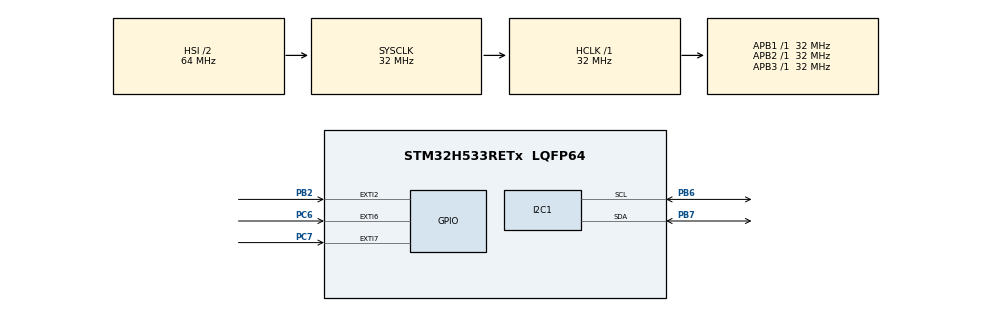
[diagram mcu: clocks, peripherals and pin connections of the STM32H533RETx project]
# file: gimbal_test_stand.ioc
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BOOTPATH.BootPathName=LEGACY
BOOTPATH.UserSelectedBootPath=LEGACY
CORTEX_M33_NS.Number-Cortex_Memory_Protection_Unit_Region0_OTP_RO_AREAS_Settings=MPU_REGION_NUMBER0
CORTEX_M33_NS.default_mode_Activation=1
CORTEX_M33_NS.userName=CORTEX_M33
I2C1.Timing=0x00707CBB
Mcu.Family=STM32H5
Mcu.Name=STM32H533RETx
Mcu.Package=LQFP64
NUCLEO-H533RE.BUTTON=1
NUCLEO-H533RE.LD4=true
NUCLEO-H533RE.VCP=true
NVIC.EXTI13_IRQn=true\:0\:0\:false\:false\:true\:false\:true\:true
NVIC.PriorityGroup=NVIC_PRIORITYGROUP_4
PA13(JTMS/SWDIO).GPIO_Label=SWDIO
PA13(JTMS/SWDIO).Signal=DEBUG_JTMS-SWDIO
PA14(JTCK/SWCLK).GPIO_Label=SWCLK
PA14(JTCK/SWCLK).Signal=DEBUG_JTCK-SWCLK
PA15(JTDI).GPIO_Label=JTDI
PA15(JTDI).Signal=DEBUG_JTDI
PA2.Signal=USART2_TX
PA3.Signal=USART2_RX
PA8.Signal=I2C3_SCL
PB2.Signal=GPXTI2
PB3(JTDO/TRACESWO).GPIO_Label=SWO
PB3(JTDO/TRACESWO).Signal=DEBUG_JTDO-SWO
PB6.Mode=I2C
PB6.Signal=I2C1_SCL
PB7.Mode=I2C
PB7.Signal=I2C1_SDA
PC6.Signal=GPXTI6
PC7.Signal=GPXTI7
PC9.Signal=I2C3_SDA
ProjectManager.HeapSize=0x200
ProjectManager.StackSize=0x400
ProjectManager.TargetToolchain=CMake
RCC.ADCFreq_Value=32000000
RCC.AHBFreq_Value=32000000
RCC.APB1Freq_Value=32000000
RCC.APB1TimFreq_Value=32000000
RCC.APB2Freq_Value=32000000
RCC.APB2TimFreq_Value=32000000
RCC.APB3Freq_Value=32000000
RCC.CSI_VALUE=4000000
RCC.CortexFreq_Value=32000000
RCC.EPOD_VALUE=4000000
RCC.HCLKFreq_Value=32000000
RCC.HSE_VALUE=25000000
RCC.HSI48_VALUE=48000000
RCC.HSI_VALUE=64000000
RCC.LSE_VALUE=32768
RCC.LSIRC_VALUE=32000
RCC.SYSCLKFreq_VALUE=32000000
RCC.USBFreq_Value=48000000
RCC.VCOOutputFreq_Value=516000000
VP_BOOTPATH_VS_BOOTPATH.Mode=BP_Activate
VP_CORTEX_M33_NS_VS_Hclk.Mode=Hclk_Mode
VP_ICACHE_VS_ICACHE.Mode=DirectMappedCache
VP_MEMORYMAP_VS_MEMORYMAP.Mode=CurAppReg
VP_NUCLEO-H533RE_VS_BSP_COMMON.Mode=COMMON
VP_PWR_VS_LPOM.Mode=PowerOptimisation
VP_PWR_VS_SECSignals.Mode=Security/Privilege
board=NUCLEO-H533RE

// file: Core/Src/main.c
/* USER CODE BEGIN Header */
/**
  ******************************************************************************
  * @file           : main.c
  * @brief          : Main program body
  ******************************************************************************
  * @attention
  *
  * Copyright (c) 2026 STMicroelectronics.
  * All rights reserved.
  *
  * This software is licensed under terms that can be found in the LICENSE file
  * in the root directory of this software component.
  * If no LICENSE file comes with this software, it is provided AS-IS.
  *
  ******************************************************************************
  */
/* USER CODE END Header */
#include "main.h"

/* USER CODE BEGIN Includes */
#include "as5600.h"

/* USER CODE END Includes */

COM_InitTypeDef BspCOMInit;

I2C_HandleTypeDef hi2c1;

/* USER CODE BEGIN PV */
static as5600_t g_as5600;
/* USER CODE END PV */

void SystemClock_Config(void);
static void MPU_Config(void);
static void MX_GPIO_Init(void);
static void MX_ICACHE_Init(void);
static void MX_I2C1_Init(void);

int main(void)
{

  /* MCU Configuration--------------------------------------------------------*/

  /* MPU Configuration--------------------------------------------------------*/
  MPU_Config();

  /* Reset of all peripherals, Initializes the Flash interface and the Systick. */
  HAL_Init();

  /* Configure the system clock */
  SystemClock_Config();

  /* Initialize all configured peripherals */
  MX_GPIO_Init();
  MX_ICACHE_Init();
  MX_I2C1_Init();
  /* USER CODE BEGIN 2 */

if (as5600_init(&g_as5600, &hi2c1, 10u) != AS5600_OK)
{
    Error_Handler();
}

  /* USER CODE END 2 */

  /* Initialize leds */
  BSP_LED_Init(LED_GREEN);

  /* Initialize USER push-button, will be used to trigger an interrupt each time it's pressed.*/
  BSP_PB_Init(BUTTON_USER, BUTTON_MODE_EXTI);

  /* Initialize COM1 port (115200, 8 bits (7-bit data + 1 stop bit), no parity */
  BspCOMInit.BaudRate   = 115200;
  BspCOMInit.WordLength = COM_WORDLENGTH_8B;
  BspCOMInit.StopBits   = COM_STOPBITS_1;
  BspCOMInit.Parity     = COM_PARITY_NONE;
  BspCOMInit.HwFlowCtl  = COM_HWCONTROL_NONE;
  if (BSP_COM_Init(COM1, &BspCOMInit) != BSP_ERROR_NONE)
  {
    Error_Handler();
  }

  /* Infinite loop */
  while (1)
  {

  }
}

void SystemClock_Config(void)
{
  RCC_OscInitTypeDef RCC_OscInitStruct = {0};
  RCC_ClkInitTypeDef RCC_ClkInitStruct = {0};

  /** Configure the main internal regulator output voltage
  */
  __HAL_PWR_VOLTAGESCALING_CONFIG(PWR_REGULATOR_VOLTAGE_SCALE3);

  while(!__HAL_PWR_GET_FLAG(PWR_FLAG_VOSRDY)) {}

  /** Initializes the RCC Oscillators according to the specified parameters
  * in the RCC_OscInitTypeDef structure.
  */
  RCC_OscInitStruct.OscillatorType = RCC_OSCILLATORTYPE_HSI;
  RCC_OscInitStruct.HSIState = RCC_HSI_ON;
  RCC_OscInitStruct.HSIDiv = RCC_HSI_DIV2;
  RCC_OscInitStruct.HSICalibrationValue = RCC_HSICALIBRATION_DEFAULT;
  RCC_OscInitStruct.PLL.PLLState = RCC_PLL_NONE;
  if (HAL_RCC_OscConfig(&RCC_OscInitStruct) != HAL_OK)
  {
    Error_Handler();
  }

  /** Initializes the CPU, AHB and APB buses clocks
  */
  RCC_ClkInitStruct.ClockType = RCC_CLOCKTYPE_HCLK|RCC_CLOCKTYPE_SYSCLK
                              |RCC_CLOCKTYPE_PCLK1|RCC_CLOCKTYPE_PCLK2
                              |RCC_CLOCKTYPE_PCLK3;
  RCC_ClkInitStruct.SYSCLKSource = RCC_SYSCLKSOURCE_HSI;
  RCC_ClkInitStruct.AHBCLKDivider = RCC_SYSCLK_DIV1;
  RCC_ClkInitStruct.APB1CLKDivider = RCC_HCLK_DIV1;
  RCC_ClkInitStruct.APB2CLKDivider = RCC_HCLK_DIV1;
  RCC_ClkInitStruct.APB3CLKDivider = RCC_HCLK_DIV1;

  if (HAL_RCC_ClockConfig(&RCC_ClkInitStruct, FLASH_LATENCY_1) != HAL_OK)
  {
    Error_Handler();
  }

  /** Configure the programming delay
  */
  __HAL_FLASH_SET_PROGRAM_DELAY(FLASH_PROGRAMMING_DELAY_0);
}

static void MX_I2C1_Init(void)
{

  hi2c1.Instance = I2C1;
  hi2c1.Init.Timing = 0x00707CBB;
  hi2c1.Init.OwnAddress1 = 0;
  hi2c1.Init.AddressingMode = I2C_ADDRESSINGMODE_7BIT;
  hi2c1.Init.DualAddressMode = I2C_DUALADDRESS_DISABLE;
  hi2c1.Init.OwnAddress2 = 0;
  hi2c1.Init.OwnAddress2Masks = I2C_OA2_NOMASK;
  hi2c1.Init.GeneralCallMode = I2C_GENERALCALL_DISABLE;
  hi2c1.Init.NoStretchMode = I2C_NOSTRETCH_DISABLE;
  if (HAL_I2C_Init(&hi2c1) != HAL_OK)
  {
    Error_Handler();
  }

  /** Configure Analogue filter
  */
  if (HAL_I2CEx_ConfigAnalogFilter(&hi2c1, I2C_ANALOGFILTER_ENABLE) != HAL_OK)
  {
    Error_Handler();
  }

  /** Configure Digital filter
  */
  if (HAL_I2CEx_ConfigDigitalFilter(&hi2c1, 0) != HAL_OK)
  {
    Error_Handler();
  }

}

static void MX_ICACHE_Init(void)
{

  /** Enable instruction cache in 1-way (direct mapped cache)
  */
  if (HAL_ICACHE_ConfigAssociativityMode(ICACHE_1WAY) != HAL_OK)
  {
    Error_Handler();
  }
  if (HAL_ICACHE_Enable() != HAL_OK)
  {
    Error_Handler();
  }

}

static void MX_GPIO_Init(void)
{
  GPIO_InitTypeDef GPIO_InitStruct = {0};

  /* GPIO Ports Clock Enable */
  __HAL_RCC_GPIOB_CLK_ENABLE();
  __HAL_RCC_GPIOC_CLK_ENABLE();
  __HAL_RCC_GPIOA_CLK_ENABLE();

  /*Configure GPIO pin : PB2 */
  GPIO_InitStruct.Pin = GPIO_PIN_2;
  GPIO_InitStruct.Mode = GPIO_MODE_IT_RISING;
  GPIO_InitStruct.Pull = GPIO_NOPULL;
  HAL_GPIO_Init(GPIOB, &GPIO_InitStruct);

  /*Configure GPIO pins : PC6 PC7 */
  GPIO_InitStruct.Pin = GPIO_PIN_6|GPIO_PIN_7;
  GPIO_InitStruct.Mode = GPIO_MODE_IT_RISING;
  GPIO_InitStruct.Pull = GPIO_NOPULL;
  HAL_GPIO_Init(GPIOC, &GPIO_InitStruct);

  /*Configure GPIO pin : PC9 */
  GPIO_InitStruct.Pin = GPIO_PIN_9;
  GPIO_InitStruct.Mode = GPIO_MODE_AF_OD;
  GPIO_InitStruct.Pull = GPIO_NOPULL;
  GPIO_InitStruct.Speed = GPIO_SPEED_FREQ_LOW;
  GPIO_InitStruct.Alternate = GPIO_AF4_I2C3;
  HAL_GPIO_Init(GPIOC, &GPIO_InitStruct);

  /*Configure GPIO pin : PA8 */
  GPIO_InitStruct.Pin = GPIO_PIN_8;
  GPIO_InitStruct.Mode = GPIO_MODE_AF_OD;
  GPIO_InitStruct.Pull = GPIO_NOPULL;
  GPIO_InitStruct.Speed = GPIO_SPEED_FREQ_LOW;
  GPIO_InitStruct.Alternate = GPIO_AF4_I2C3;
  HAL_GPIO_Init(GPIOA, &GPIO_InitStruct);

}

 /* MPU Configuration */

void MPU_Config(void)
{
  MPU_Region_InitTypeDef MPU_InitStruct = {0};
  MPU_Attributes_InitTypeDef MPU_AttributesInit = {0};

  /* Disables the MPU */
  HAL_MPU_Disable();

  /** Initializes and configures the Region 0 and the memory to be protected
  */
  MPU_InitStruct.Enable = MPU_REGION_ENABLE;
  MPU_InitStruct.Number = MPU_REGION_NUMBER0;
  MPU_InitStruct.BaseAddress = 0x08FFF000;
  MPU_InitStruct.LimitAddress = 0x08FFFFFF;
  MPU_InitStruct.AttributesIndex = MPU_ATTRIBUTES_NUMBER0;
  MPU_InitStruct.AccessPermission = MPU_REGION_ALL_RO;
  MPU_InitStruct.DisableExec = MPU_INSTRUCTION_ACCESS_DISABLE;
  MPU_InitStruct.IsShareable = MPU_ACCESS_NOT_SHAREABLE;

  HAL_MPU_ConfigRegion(&MPU_InitStruct);

  /** Initializes and configures the Attribute 0 and the memory to be protected
  */
  MPU_AttributesInit.Number = MPU_ATTRIBUTES_NUMBER0;
  MPU_AttributesInit.Attributes = INNER_OUTER(MPU_NOT_CACHEABLE);

  HAL_MPU_ConfigMemoryAttributes(&MPU_AttributesInit);
  /* Enables the MPU */
  HAL_MPU_Enable(MPU_PRIVILEGED_DEFAULT);

}

void Error_Handler(void)
{
  __disable_irq();
  while (1)
  {
  }
}
